# LRFDRFE register map
Vendor: Texas Instruments
Registers are 32-bit, access per field, reset 0x0 unless marked. A register's access mark holds for its fields unless they carry their own. Offsets are as the file gives them; [hi:lo] are bit positions; {n}, {i} and the like mark numbered series; 'fields as' and 'values as' point back to an identical list.

## LRFDRFE (part 2 of 2)
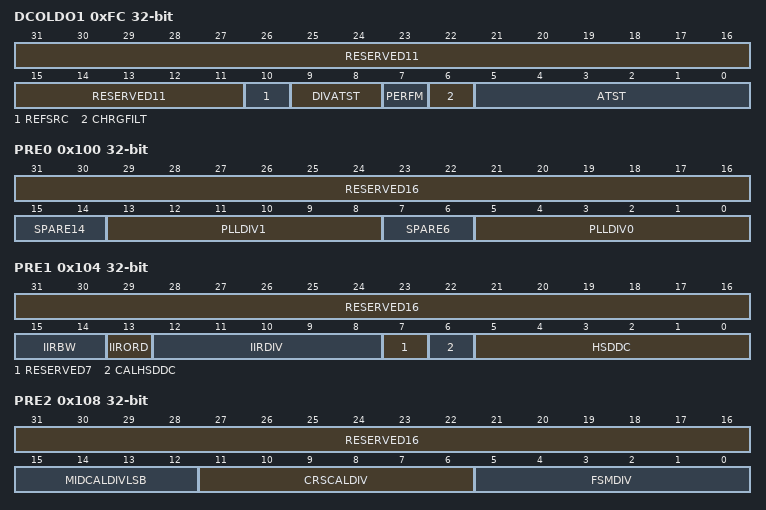
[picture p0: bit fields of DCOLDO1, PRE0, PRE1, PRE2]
0xFC DCOLDO1 — Internal. Only to be used through TI provided API.
  [31:11] RESERVED11 ro — Internal. Only to be used through TI provided API.
  [10] REFSRC rw — Internal. Only to be used through TI provided API.
    1=BAW (Internal. Only to be used through TI provided API.); 0=XTAL (Internal. Only to be used through TI provided API.)
  [9:8] DIVATST rw — Internal. Only to be used through TI provided API.
    3=ONES (Internal. Only to be used through TI provided API.); 0=ZEROS (Internal. Only to be used through TI provided API.)
  [7] PERFM rw — Internal. Only to be used through TI provided API.
    1=EN (Internal. Only to be used through TI provided API.); 0=DIS (Internal. Only to be used through TI provided API.)
  [6] CHRGFILT rw — Internal. Only to be used through TI provided API.
    values as PERFM
  [5:0] ATST rw — Internal. Only to be used through TI provided API.
    32=VSSANA (Internal. Only to be used through TI provided API.); 1=FIRST_OUT (Internal. Only to be used through TI provided API.); 0=LDO_OUT (Internal. Only to be used through TI provided API.)
0x100 PRE0 — Internal. Only to be used through TI provided API.
  [31:16] RESERVED16 ro — Internal. Only to be used through TI provided API.
  [15:14] SPARE14 rw — Internal. Only to be used through TI provided API.
    3=ALLONES (Internal. Only to be used through TI provided API.); 0=ALLZEROS (Internal. Only to be used through TI provided API.)
  [13:8] PLLDIV1 rw — Internal. Only to be used through TI provided API.
    63=ALLONES (Internal. Only to be used through TI provided API.); 0=ALLZEROS (Internal. Only to be used through TI provided API.)
  [7:6] SPARE6 rw — Internal. Only to be used through TI provided API.
    values as SPARE14
  [5:0] PLLDIV0 rw — Internal. Only to be used through TI provided API.
    values as PLLDIV1
0x104 PRE1 — Internal. Only to be used through TI provided API.
  [31:16] RESERVED16 ro — Internal. Only to be used through TI provided API.
  [15:14] IIRBW rw — Internal. Only to be used through TI provided API.
    3=K16 (Internal. Only to be used through TI provided API.); 2=K8 (Internal. Only to be used through TI provided API.); 1=K4 (Internal. Only to be used through TI provided API.); 0=K2 (Internal. Only to be used through TI provided API.)
  [13] IIRORD rw — Internal. Only to be used through TI provided API.
    1=SECOND (Internal. Only to be used through TI provided API.); 0=FIRST (Internal. Only to be used through TI provided API.)
  [12:8] IIRDIV rw — Internal. Only to be used through TI provided API.
    31=ALLONES (Internal. Only to be used through TI provided API.); 0=ALLZEROS (Internal. Only to be used through TI provided API.)
  [7] RESERVED7 ro — Internal. Only to be used through TI provided API.
  [6] CALHSDDC rw — Internal. Only to be used through TI provided API.
    1=GATE (Internal. Only to be used through TI provided API.); 0=NOGATE (Internal. Only to be used through TI provided API.)
  [5:0] HSDDC rw — Internal. Only to be used through TI provided API.
    values as PRE0.PLLDIV1
0x108 PRE2 — Internal. Only to be used through TI provided API.
  [31:16] RESERVED16 ro — Internal. Only to be used through TI provided API.
  [15:12] MIDCALDIVLSB rw — Internal. Only to be used through TI provided API.
    15=ALLONES (Internal. Only to be used through TI provided API.); 0=ALLZEROS (Internal. Only to be used through TI provided API.)
  [11:6] CRSCALDIV rw — Internal. Only to be used through TI provided API.
    values as PRE0.PLLDIV1
  [5:0] FSMDIV rw — Internal. Only to be used through TI provided API.
    values as PRE0.PLLDIV1
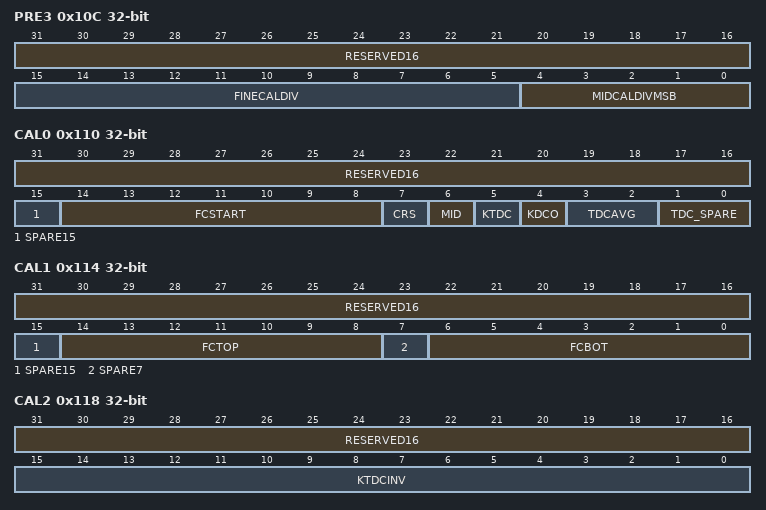
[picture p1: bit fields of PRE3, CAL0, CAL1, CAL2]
0x10C PRE3 — Internal. Only to be used through TI provided API.
  [31:16] RESERVED16 ro — Internal. Only to be used through TI provided API.
  [15:5] FINECALDIV rw — Internal. Only to be used through TI provided API.
    0x7FF=ALLONES (Internal. Only to be used through TI provided API.); 0=ALLZEROS (Internal. Only to be used through TI provided API.)
  [4:0] MIDCALDIVMSB rw — Internal. Only to be used through TI provided API.
    values as PRE1.IIRDIV
0x110 CAL0 — Internal. Only to be used through TI provided API.
  [31:16] RESERVED16 ro — Internal. Only to be used through TI provided API.
  [15] SPARE15 rw — Internal. Only to be used through TI provided API.
    1=ONE (Internal. Only to be used through TI provided API.); 0=ZERO (Internal. Only to be used through TI provided API.)
  [14:8] FCSTART rw — Internal. Only to be used through TI provided API.
    127=ALLONES (Internal. Only to be used through TI provided API.); 0=ALLZEROS (Internal. Only to be used through TI provided API.)
  [7] CRS rw — Internal. Only to be used through TI provided API.
    values as DCOLDO1.PERFM
  [6] MID rw — Internal. Only to be used through TI provided API.
    values as DCOLDO1.PERFM
  [5] KTDC rw — Internal. Only to be used through TI provided API.
    values as DCOLDO1.PERFM
  [4] KDCO rw — Internal. Only to be used through TI provided API.
    values as DCOLDO1.PERFM
  [3:2] TDCAVG rw — Internal. Only to be used through TI provided API.
    3=REPEAT_8_TIMES (Internal. Only to be used through TI provided API.); 2=REPEAT_4_TIMES (Internal. Only to be used through TI provided API.); 1=REPEAT_2_TIMES (Internal. Only to be used through TI provided API.); 0=REPEAT_1_TIME (Internal. Only to be used through TI provided API.)
  [1:0] TDC_SPARE rw — Internal. Only to be used through TI provided API.
    values as PRE0.SPARE14
0x114 CAL1 — Internal. Only to be used through TI provided API.
  [31:16] RESERVED16 ro — Internal. Only to be used through TI provided API.
  [15] SPARE15 rw — Internal. Only to be used through TI provided API.
    values as CAL0.SPARE15
  [14:8] FCTOP rw — Internal. Only to be used through TI provided API.
    values as CAL0.FCSTART
  [7] SPARE7 rw — Internal. Only to be used through TI provided API.
    values as CAL0.SPARE15
  [6:0] FCBOT rw — Internal. Only to be used through TI provided API.
    values as CAL0.FCSTART
0x118 CAL2 — Internal. Only to be used through TI provided API.
  [31:16] RESERVED16 ro — Internal. Only to be used through TI provided API.
  [15:0] KTDCINV rw — Internal. Only to be used through TI provided API.
    0xFFFF=ALLONES (Internal. Only to be used through TI provided API.); 0=ALLZEROS (Internal. Only to be used through TI provided API.)
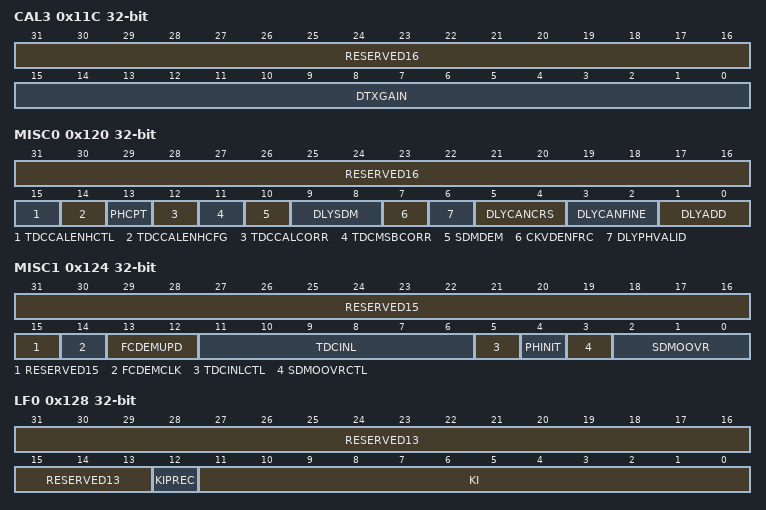
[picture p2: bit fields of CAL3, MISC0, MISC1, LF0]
0x11C CAL3 — Internal. Only to be used through TI provided API.
  [31:16] RESERVED16 ro — Internal. Only to be used through TI provided API.
  [15:0] DTXGAIN rw — Internal. Only to be used through TI provided API.
    values as CAL2.KTDCINV
0x120 MISC0 — Internal. Only to be used through TI provided API.
  [31:16] RESERVED16 ro — Internal. Only to be used through TI provided API.
  [15] TDCCALENHCTL rw — Internal. Only to be used through TI provided API.
    values as DCOLDO1.PERFM
  [14] TDCCALENHCFG rw — Internal. Only to be used through TI provided API.
    1=MAXOFFSET (Internal. Only to be used through TI provided API.); 0=MINOFFSET (Internal. Only to be used through TI provided API.)
  [13] PHCPT rw — Internal. Only to be used through TI provided API.
    1=ASYNC (Internal. Only to be used through TI provided API.); 0=SYNC (Internal. Only to be used through TI provided API.)
  [12] TDCCALCORR rw — Internal. Only to be used through TI provided API.
    values as DCOLDO1.PERFM
  [11] TDCMSBCORR rw — Internal. Only to be used through TI provided API.
    values as DCOLDO1.PERFM
  [10] SDMDEM rw — Internal. Only to be used through TI provided API.
    values as DCOLDO1.PERFM
  [9:8] DLYSDM rw — Internal. Only to be used through TI provided API.
    {v}=CKVD16_{v}_PER (Internal. Only to be used through TI provided API.) (v=0..3)
  [7] CKVDENFRC rw — Internal. Only to be used through TI provided API.
    values as DCOLDO1.PERFM
  [6] DLYPHVALID rw — Internal. Only to be used through TI provided API.
    1=NOQUAL (Internal. Only to be used through TI provided API.); 0=QUAL (Internal. Only to be used through TI provided API.)
  [5:4] DLYCANCRS rw — Internal. Only to be used through TI provided API.
    {v}=CKVD64_{v}_PER (Internal. Only to be used through TI provided API.) (v=0..3)
  [3:2] DLYCANFINE rw — Internal. Only to be used through TI provided API.
    {v}=CKVD16_{v+1}_PER (Internal. Only to be used through TI provided API.) (v=0..3)
  [1:0] DLYADD rw — Internal. Only to be used through TI provided API.
    values as DLYCANCRS
0x124 MISC1 — Internal. Only to be used through TI provided API.
  [31:15] RESERVED15 ro — Internal. Only to be used through TI provided API.
  [14] FCDEMCLK rw — Internal. Only to be used through TI provided API.
    1=CKVD64 (Internal. Only to be used through TI provided API.); 0=CKCD16 (Internal. Only to be used through TI provided API.)
  [13:12] FCDEMUPD rw — Internal. Only to be used through TI provided API.
    3=SDM_XOR_PH_ERR (Internal. Only to be used through TI provided API.); 2=SDM (Internal. Only to be used through TI provided API.); 1=PH_ERR (Internal. Only to be used through TI provided API.); 0=DEFAULT (Internal. Only to be used through TI provided API.)
  [11:6] TDCINL rw — Internal. Only to be used through TI provided API.
    63=ONES (Internal. Only to be used through TI provided API.); 0=ZEROS (Internal. Only to be used through TI provided API.)
  [5] TDCINLCTL rw — Internal. Only to be used through TI provided API.
    values as DCOLDO1.PERFM
  [4] PHINIT rw — Internal. Only to be used through TI provided API.
    1=UNKNOWN (Internal. Only to be used through TI provided API.); 0=KNOWN (Internal. Only to be used through TI provided API.)
  [3] SDMOOVRCTL rw — Internal. Only to be used through TI provided API.
    values as DCOLDO1.PERFM
  [2:0] SDMOOVR rw — Internal. Only to be used through TI provided API.
    7=ALLONES (Internal. Only to be used through TI provided API.); 0=ALLZEROS (Internal. Only to be used through TI provided API.)
0x128 LF0 — Internal. Only to be used through TI provided API.
  [31:13] RESERVED13 ro — Internal. Only to be used through TI provided API.
  [12] KIPREC rw — Internal. Only to be used through TI provided API.
    1=HIGH (Internal. Only to be used through TI provided API.); 0=LOW (Internal. Only to be used through TI provided API.)
  [11:0] KI rw — Internal. Only to be used through TI provided API.
    0xFFF=ALLONES (Internal. Only to be used through TI provided API.); 0=ALLZEROS (Internal. Only to be used through TI provided API.)
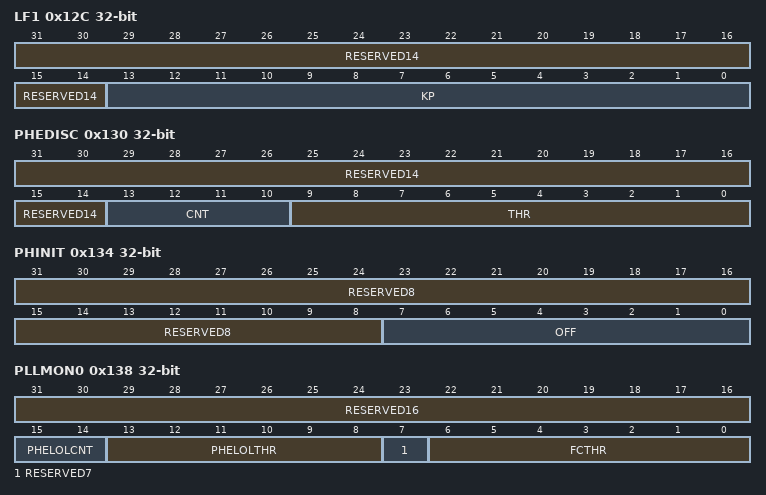
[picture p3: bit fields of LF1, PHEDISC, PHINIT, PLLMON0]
0x12C LF1 — Internal. Only to be used through TI provided API.
  [31:14] RESERVED14 ro — Internal. Only to be used through TI provided API.
  [13:0] KP rw — Internal. Only to be used through TI provided API.
    0x3FFF=ALLONES (Internal. Only to be used through TI provided API.); 0=ALLZEROS (Internal. Only to be used through TI provided API.)
0x130 PHEDISC — Internal. Only to be used through TI provided API.
  [31:14] RESERVED14 ro — Internal. Only to be used through TI provided API.
  [13:10] CNT rw — Internal. Only to be used through TI provided API.
    values as PRE2.MIDCALDIVLSB
  [9:0] THR rw — Internal. Only to be used through TI provided API.
    0x3FF=ALLONES (Internal. Only to be used through TI provided API.); 0=ALLZEROS (Internal. Only to be used through TI provided API.)
0x134 PHINIT — Internal. Only to be used through TI provided API.
  [31:8] RESERVED8 ro — Internal. Only to be used through TI provided API.
  [7:0] OFF rw — Internal. Only to be used through TI provided API.
    255=ALLONES (Internal. Only to be used through TI provided API.); 0=ALLZEROS (Internal. Only to be used through TI provided API.)
0x138 PLLMON0 — Internal. Only to be used through TI provided API.
  [31:16] RESERVED16 ro — Internal. Only to be used through TI provided API.
  [15:14] PHELOLCNT rw — Internal. Only to be used through TI provided API.
    3=REFCLK_128_PER (Internal. Only to be used through TI provided API.); 2=REFCLK_64_PER (Internal. Only to be used through TI provided API.); 1=REFCLK_32_PER (Internal. Only to be used through TI provided API.); 0=REFCLK_16_PER (Internal. Only to be used through TI provided API.)
  [13:8] PHELOLTHR rw — Internal. Only to be used through TI provided API.
    values as PRE0.PLLDIV1
  [7] RESERVED7 ro — Internal. Only to be used through TI provided API.
  [6:0] FCTHR rw — Internal. Only to be used through TI provided API.
    values as CAL0.FCSTART
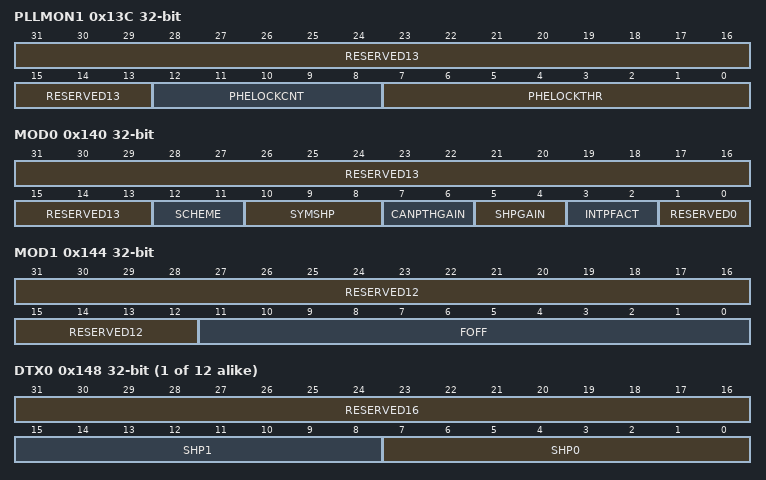
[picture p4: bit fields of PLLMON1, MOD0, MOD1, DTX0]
0x13C PLLMON1 — Internal. Only to be used through TI provided API.
  [31:13] RESERVED13 ro — Internal. Only to be used through TI provided API.
  [12:8] PHELOCKCNT rw — Internal. Only to be used through TI provided API.
    values as PRE1.IIRDIV
  [7:0] PHELOCKTHR rw — Internal. Only to be used through TI provided API.
    values as PHINIT.OFF
0x140 MOD0 — Internal. Only to be used through TI provided API.
  [31:13] RESERVED13 ro — Internal. Only to be used through TI provided API.
  [12:11] SCHEME rw — Internal. Only to be used through TI provided API.
    3=TWO_POINT_MOD_FRF (Internal. Only to be used through TI provided API.); 2=INLOOP_MOD_FRF (Internal. Only to be used through TI provided API.); 1=INLOOP_MOD_FREF (Internal. Only to be used through TI provided API.); 0=NC (Internal. Only to be used through TI provided API.)
  [10:8] SYMSHP rw — Internal. Only to be used through TI provided API.
    4=CHIRP (Internal. Only to be used through TI provided API.); 3=SHAPEDZIGBEE (Internal. Only to be used through TI provided API.); 2=PCWSPSK (Internal. Only to be used through TI provided API.); 1=ZIGBEE (Internal. Only to be used through TI provided API.); 0=SHAPEDFSK (Internal. Only to be used through TI provided API.)
  [7:6] CANPTHGAIN rw — Internal. Only to be used through TI provided API.
    {v}=TWO_POW_M_{v+15} (Internal. Only to be used through TI provided API.) (v=0..3)
  [5:4] SHPGAIN rw — Internal. Only to be used through TI provided API.
    3=X8 (Internal. Only to be used through TI provided API.); 2=X4 (Internal. Only to be used through TI provided API.); 1=X2 (Internal. Only to be used through TI provided API.); 0=Internal. Only to be used through TI provided API.
  [3:2] INTPFACT rw — Internal. Only to be used through TI provided API.
    3=ILLEGAL1 (Internal. Only to be used through TI provided API.); 2=INTP_BY_32 (Internal. Only to be used through TI provided API.); 1=INTP_BY_16 (Internal. Only to be used through TI provided API.); 0=ILLEGAL0 (Internal. Only to be used through TI provided API.)
  [1:0] RESERVED0 ro — Internal. Only to be used through TI provided API.
0x144 MOD1 — Internal. Only to be used through TI provided API.
  [31:12] RESERVED12 ro — Internal. Only to be used through TI provided API.
  [11:0] FOFF rw — Internal. Only to be used through TI provided API.
    values as LF0.KI
{0x148+4i} DTX{i} (i=0..11) — Internal. Only to be used through TI provided API.
  [31:16] RESERVED16 ro — Internal. Only to be used through TI provided API.
  [15:8] SHP{2i+1} rw — Internal. Only to be used through TI provided API.
    values as PHINIT.OFF
  [7:0] SHP{2i} rw — Internal. Only to be used through TI provided API.
    values as PHINIT.OFF
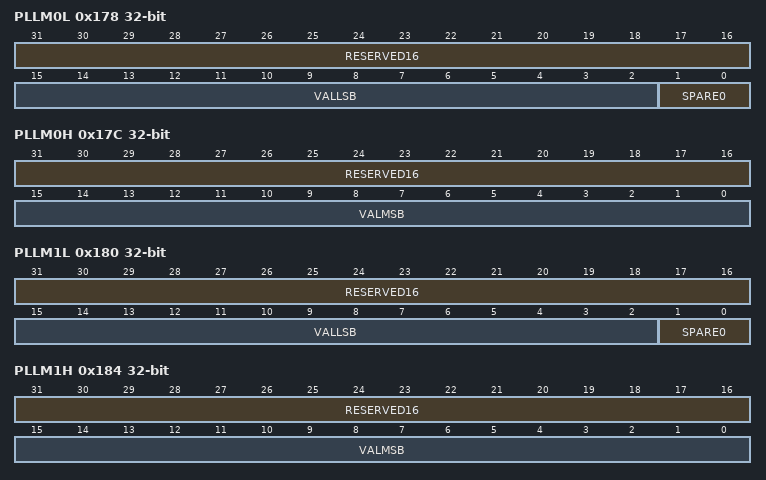
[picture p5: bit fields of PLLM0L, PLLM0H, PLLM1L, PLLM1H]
0x178 PLLM0L — Internal. Only to be used through TI provided API.
  [31:16] RESERVED16 ro — Internal. Only to be used through TI provided API.
  [15:2] VALLSB rw — Internal. Only to be used through TI provided API.
    values as LF1.KP
  [1:0] SPARE0 rw — Internal. Only to be used through TI provided API.
    values as PRE0.SPARE14
0x17C PLLM0H — Internal. Only to be used through TI provided API.
  [31:16] RESERVED16 ro — Internal. Only to be used through TI provided API.
  [15:0] VALMSB rw — Internal. Only to be used through TI provided API.
    values as CAL2.KTDCINV
0x180 PLLM1L — Internal. Only to be used through TI provided API.
  fields as PLLM0L
0x184 PLLM1H — Internal. Only to be used through TI provided API.
  fields as PLLM0H
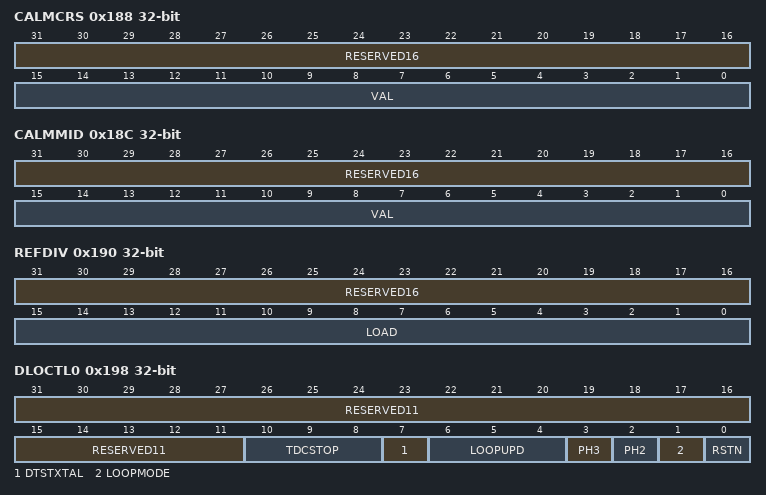
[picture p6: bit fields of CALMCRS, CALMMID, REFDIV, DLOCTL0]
0x188 CALMCRS — Internal. Only to be used through TI provided API.
  [31:16] RESERVED16 ro — Internal. Only to be used through TI provided API.
  [15:0] VAL rw — Internal. Only to be used through TI provided API.
    values as CAL2.KTDCINV
0x18C CALMMID — Internal. Only to be used through TI provided API.
  fields as CALMCRS
0x190 REFDIV — Internal. Only to be used through TI provided API.
  [31:16] RESERVED16 ro — Internal. Only to be used through TI provided API.
  [15:0] LOAD rw — Internal. Only to be used through TI provided API.
    values as CAL2.KTDCINV
0x198 DLOCTL0 — Internal. Only to be used through TI provided API.
  [31:11] RESERVED11 ro — Internal. Only to be used through TI provided API.
  [10:8] TDCSTOP rw — Internal. Only to be used through TI provided API.
    1=OPEN (Internal. Only to be used through TI provided API.); 0=CLOSED (Internal. Only to be used through TI provided API.)
  [7] DTSTXTAL rw — Internal. Only to be used through TI provided API.
    values as CAL0.SPARE15
  [6:4] LOOPUPD rw — Internal. Only to be used through TI provided API.
    1=ALT (Internal. Only to be used through TI provided API.); 0=DEF (Internal. Only to be used through TI provided API.)
  [3] PH3 rw — Internal. Only to be used through TI provided API.
    1=START (Internal. Only to be used through TI provided API.); 0=HALT (Internal. Only to be used through TI provided API.)
  [2] PH2 rw — Internal. Only to be used through TI provided API.
    values as PH3
  [1] LOOPMODE rw — Internal. Only to be used through TI provided API.
    values as TDCSTOP
  [0] RSTN rw — Internal. Only to be used through TI provided API.
    1=ACTIVE (Internal. Only to be used through TI provided API.); 0=RESET (Internal. Only to be used through TI provided API.)
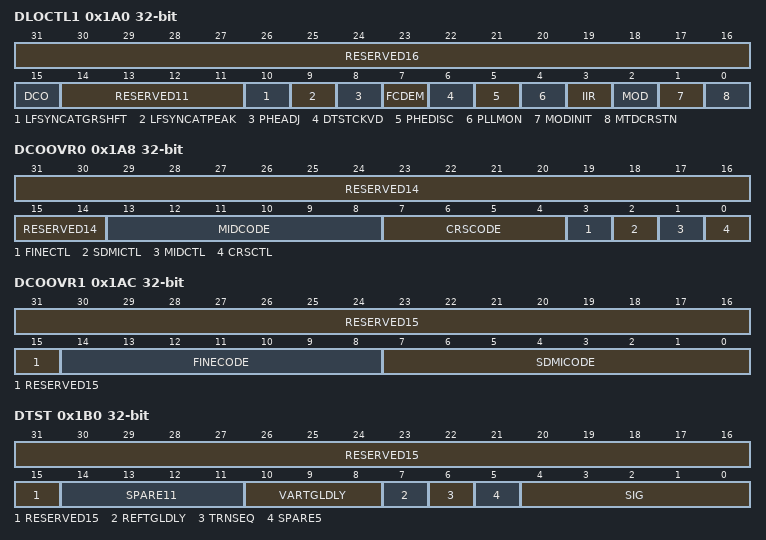
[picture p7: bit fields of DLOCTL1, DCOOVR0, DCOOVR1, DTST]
0x1A0 DLOCTL1 — Internal. Only to be used through TI provided API.
  [31:16] RESERVED16 ro — Internal. Only to be used through TI provided API.
  [15] DCO rw — Internal. Only to be used through TI provided API.
    values as DCOLDO1.PERFM
  [14:11] RESERVED11 ro — Internal. Only to be used through TI provided API.
  [10] LFSYNCATGRSHFT rw — Internal. Only to be used through TI provided API.
    values as DCOLDO1.PERFM
  [9] LFSYNCATPEAK rw — Internal. Only to be used through TI provided API.
    values as DCOLDO1.PERFM
  [8] PHEADJ rw — Internal. Only to be used through TI provided API.
    values as DCOLDO1.PERFM
  [7] FCDEM rw — Internal. Only to be used through TI provided API.
    values as DCOLDO1.PERFM
  [6] DTSTCKVD rw — Internal. Only to be used through TI provided API.
    values as CAL0.SPARE15
  [5] PHEDISC rw — Internal. Only to be used through TI provided API.
    values as DCOLDO1.PERFM
  [4] PLLMON rw — Internal. Only to be used through TI provided API.
    values as DCOLDO1.PERFM
  [3] IIR rw — Internal. Only to be used through TI provided API.
    values as DCOLDO1.PERFM
  [2] MOD rw — Internal. Only to be used through TI provided API.
    values as DCOLDO1.PERFM
  [1] MODINIT rw — Internal. Only to be used through TI provided API.
    1=ACTIVATE (Internal. Only to be used through TI provided API.); 0=DEACTIVATE (Internal. Only to be used through TI provided API.)
  [0] MTDCRSTN rw — Internal. Only to be used through TI provided API.
    values as DLOCTL0.RSTN
0x1A8 DCOOVR0 — Internal. Only to be used through TI provided API.
  [31:14] RESERVED14 ro — Internal. Only to be used through TI provided API.
  [13:8] MIDCODE rw — Internal. Only to be used through TI provided API.
    values as PRE0.PLLDIV1
  [7:4] CRSCODE rw — Internal. Only to be used through TI provided API.
    values as PRE2.MIDCALDIVLSB
  [3] FINECTL rw — Internal. Only to be used through TI provided API.
    values as DCOLDO1.PERFM
  [2] SDMICTL rw — Internal. Only to be used through TI provided API.
    values as DCOLDO1.PERFM
  [1] MIDCTL rw — Internal. Only to be used through TI provided API.
    values as DCOLDO1.PERFM
  [0] CRSCTL rw — Internal. Only to be used through TI provided API.
    values as DCOLDO1.PERFM
0x1AC DCOOVR1 — Internal. Only to be used through TI provided API.
  [31:15] RESERVED15 ro — Internal. Only to be used through TI provided API.
  [14:8] FINECODE rw — Internal. Only to be used through TI provided API.
    values as CAL0.FCSTART
  [7:0] SDMICODE rw — Internal. Only to be used through TI provided API.
    values as PHINIT.OFF
0x1B0 DTST — Internal. Only to be used through TI provided API.
  [31:15] RESERVED15 ro — Internal. Only to be used through TI provided API.
  [14:11] SPARE11 rw — Internal. Only to be used through TI provided API.
    values as PRE2.MIDCALDIVLSB
  [10:8] VARTGLDLY rw — Internal. Only to be used through TI provided API.
    {v}=CLK_{v}_PER (Internal. Only to be used through TI provided API.) (v=0..7)
  [7] REFTGLDLY rw — Internal. Only to be used through TI provided API.
    1=CLK_1_PER (Internal. Only to be used through TI provided API.); 0=CLK_0_PER (Internal. Only to be used through TI provided API.)
  [6] TRNSEQ rw — Internal. Only to be used through TI provided API.
    values as DCOLDO1.PERFM
  [5] SPARE5 rw — Internal. Only to be used through TI provided API.
    values as CAL0.SPARE15
  [4:0] SIG rw — Internal. Only to be used through TI provided API.
    31=VAR_NC_15 (Internal. Only to be used through TI provided API.); 30=VAR_NC_14 (Internal. Only to be used through TI provided API.); 29=VAR_NC_13 (Internal. Only to be used through TI provided API.); 28=VAR_FCPHELFSYNC (Internal. Only to be used through TI provided API.); 27=VAR_FCPHE (Internal. Only to be used through TI provided API.); 26=VAR_LOOP_UPD_FINECODE (Internal. Only to be used through TI provided API.); 25=VAR_LOCK_FINECODE (Internal. Only to be used through TI provided API.); 24=VAR_MPX_CAN (Internal. Only to be used through TI provided API.); 23=VAR_TDCSTOP_STATUS_TDC (Internal. Only to be used through TI provided API.); 22=VAR_TDCSTOP_PHERR (Internal. Only to be used through TI provided API.); 21=VAR_PH_COMP_PHERR_TDCSTOP (Internal. Only to be used through TI provided API.); 20=VAR_PH_TDCCORR (Internal. Only to be used through TI provided API.); 19=VAR_PH_RAW (Internal. Only to be used through TI provided API.); 18=VAR_PHERR_LOWER (Internal. Only to be used through TI provided API.); 17=VAR_PHERR_UPPER (Internal. Only to be used through TI provided API.); 16=VAR_NC_0 (Internal. Only to be used through TI provided API.); {v}=REF_NC_{v} (Internal. Only to be used through TI provided API.) (v=3..15); 2=REF_FERR_MAG (Internal. Only to be used through TI provided API.); 1=REF_FSMCAL (Internal. Only to be used through TI provided API.); 0=REF_NC_0 (Internal. Only to be used through TI provided API.)
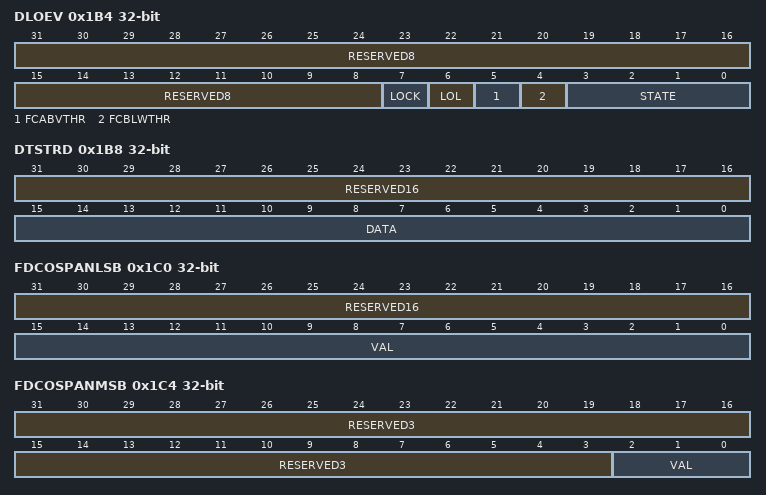
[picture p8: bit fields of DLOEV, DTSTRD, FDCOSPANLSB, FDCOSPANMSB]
0x1B4 DLOEV ro — Internal. Only to be used through TI provided API.
  [31:8] RESERVED8 — Internal. Only to be used through TI provided API.
  [7] LOCK — Internal. Only to be used through TI provided API.
    values as CAL0.SPARE15
  [6] LOL — Internal. Only to be used through TI provided API.
    values as CAL0.SPARE15
  [5] FCABVTHR — Internal. Only to be used through TI provided API.
    values as CAL0.SPARE15
  [4] FCBLWTHR — Internal. Only to be used through TI provided API.
    values as CAL0.SPARE15
  [3:0] STATE — Internal. Only to be used through TI provided API.
    values as PRE2.MIDCALDIVLSB
0x1B8 DTSTRD ro — Internal. Only to be used through TI provided API.
  [31:16] RESERVED16 — Internal. Only to be used through TI provided API.
  [15:0] DATA — Internal. Only to be used through TI provided API.
    values as CAL2.KTDCINV
0x1C0 FDCOSPANLSB ro — Internal. Only to be used through TI provided API.
  [31:16] RESERVED16 — Internal. Only to be used through TI provided API.
  [15:0] VAL — Internal. Only to be used through TI provided API.
    values as CAL2.KTDCINV
0x1C4 FDCOSPANMSB ro — Internal. Only to be used through TI provided API.
  [31:3] RESERVED3 — Internal. Only to be used through TI provided API.
  [2:0] VAL — Internal. Only to be used through TI provided API.
    values as MISC1.SDMOOVR
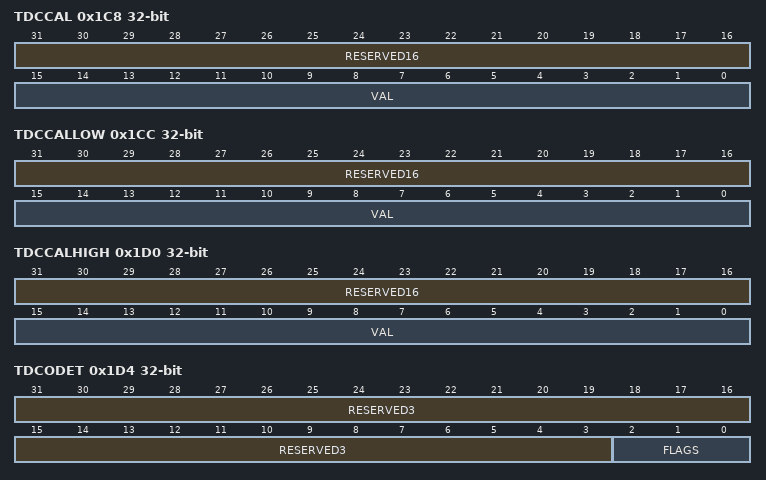
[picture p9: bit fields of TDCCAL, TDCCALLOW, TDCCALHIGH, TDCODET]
0x1C8 TDCCAL ro — Internal. Only to be used through TI provided API.
  fields as FDCOSPANLSB
0x1CC TDCCALLOW ro — Internal. Only to be used through TI provided API.
  fields as FDCOSPANLSB
0x1D0 TDCCALHIGH ro — Internal. Only to be used through TI provided API.
  fields as FDCOSPANLSB
0x1D4 TDCODET ro — Internal. Only to be used through TI provided API.
  [31:3] RESERVED3 — Internal. Only to be used through TI provided API.
  [2:0] FLAGS — Internal. Only to be used through TI provided API.
    values as MISC1.SDMOOVR
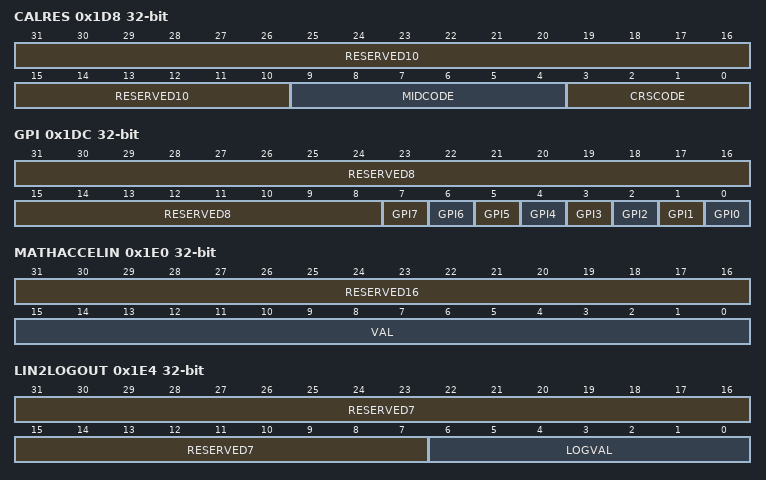
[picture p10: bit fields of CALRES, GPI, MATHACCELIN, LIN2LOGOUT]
0x1D8 CALRES ro — Internal. Only to be used through TI provided API.
  [31:10] RESERVED10 — Internal. Only to be used through TI provided API.
  [9:4] MIDCODE — Internal. Only to be used through TI provided API.
    values as PRE0.PLLDIV1
  [3:0] CRSCODE — Internal. Only to be used through TI provided API.
    values as PRE2.MIDCALDIVLSB
0x1DC GPI ro — Internal. Only to be used through TI provided API.
  [31:8] RESERVED8 — Internal. Only to be used through TI provided API.
  [n] GPI{n} (n=0..7) — Internal. Only to be used through TI provided API.
    values as CAL0.SPARE15
0x1E0 MATHACCELIN — Internal. Only to be used through TI provided API.
  fields as CALMCRS
0x1E4 LIN2LOGOUT ro — Internal. Only to be used through TI provided API.
  [31:7] RESERVED7 — Internal. Only to be used through TI provided API.
  [6:0] LOGVAL — Internal. Only to be used through TI provided API.
    values as CAL0.FCSTART
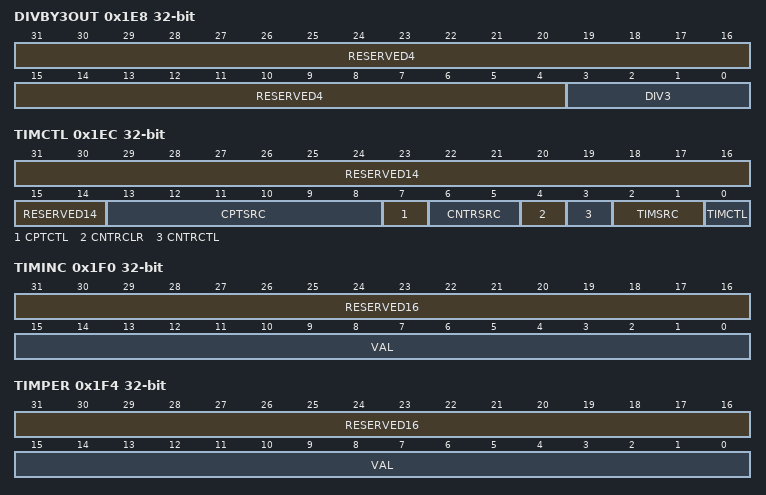
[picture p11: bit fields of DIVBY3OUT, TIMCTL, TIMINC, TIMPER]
0x1E8 DIVBY3OUT ro — Internal. Only to be used through TI provided API.
  [31:4] RESERVED4 — Internal. Only to be used through TI provided API.
  [3:0] DIV3 — Internal. Only to be used through TI provided API.
    values as PRE2.MIDCALDIVLSB
0x1EC TIMCTL — Internal. Only to be used through TI provided API.
  [31:14] RESERVED14 ro — Internal. Only to be used through TI provided API.
  [13:8] CPTSRC rw — Internal. Only to be used through TI provided API.
    values as PRE0.PLLDIV1
  [7] CPTCTL rw — Internal. Only to be used through TI provided API.
    values as DCOLDO1.PERFM
  [6:5] CNTRSRC rw — Internal. Only to be used through TI provided API.
    3=FREF (Internal. Only to be used through TI provided API.); 2=MAGN1 (Internal. Only to be used through TI provided API.); 1=MAGN0 (Internal. Only to be used through TI provided API.); 0=CLK (Internal. Only to be used through TI provided API.)
  [4] CNTRCLR rw — Internal. Only to be used through TI provided API.
    values as CAL0.SPARE15
  [3] CNTRCTL rw — Internal. Only to be used through TI provided API.
    values as DCOLDO1.PERFM
  [2:1] TIMSRC rw — Internal. Only to be used through TI provided API.
    values as CNTRSRC
  [0] TIMCTL rw — Internal. Only to be used through TI provided API.
    values as DCOLDO1.PERFM
0x1F0 TIMINC — Internal. Only to be used through TI provided API.
  fields as CALMCRS
0x1F4 TIMPER — Internal. Only to be used through TI provided API.
  fields as CALMCRS
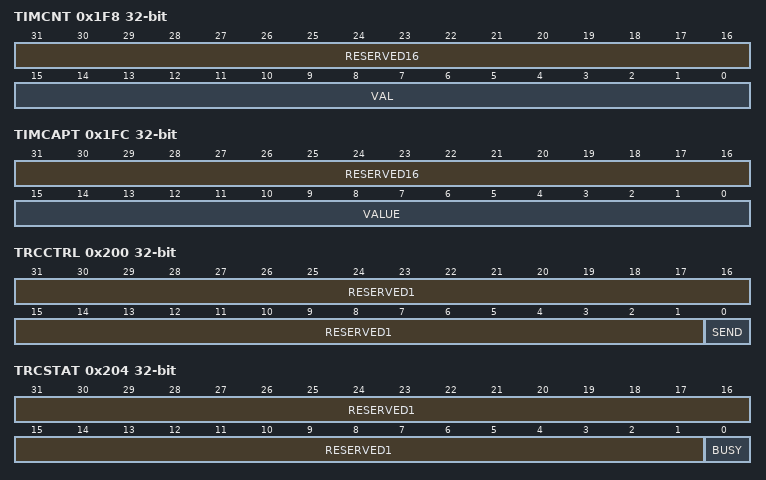
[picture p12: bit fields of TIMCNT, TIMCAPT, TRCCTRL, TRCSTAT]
0x1F8 TIMCNT ro — Internal. Only to be used through TI provided API.
  fields as FDCOSPANLSB
0x1FC TIMCAPT ro — Internal. Only to be used through TI provided API.
  [31:16] RESERVED16 — Internal. Only to be used through TI provided API.
  [15:0] VALUE — Internal. Only to be used through TI provided API.
    values as CAL2.KTDCINV
0x200 TRCCTRL — Internal. Only to be used through TI provided API.
  [31:1] RESERVED1 ro — Internal. Only to be used through TI provided API.
  [0] SEND wo — Internal. Only to be used through TI provided API.
    values as CAL0.SPARE15
0x204 TRCSTAT ro — Internal. Only to be used through TI provided API.
  [31:1] RESERVED1 — Internal. Only to be used through TI provided API.
  [0] BUSY — Internal. Only to be used through TI provided API.
    values as CAL0.SPARE15
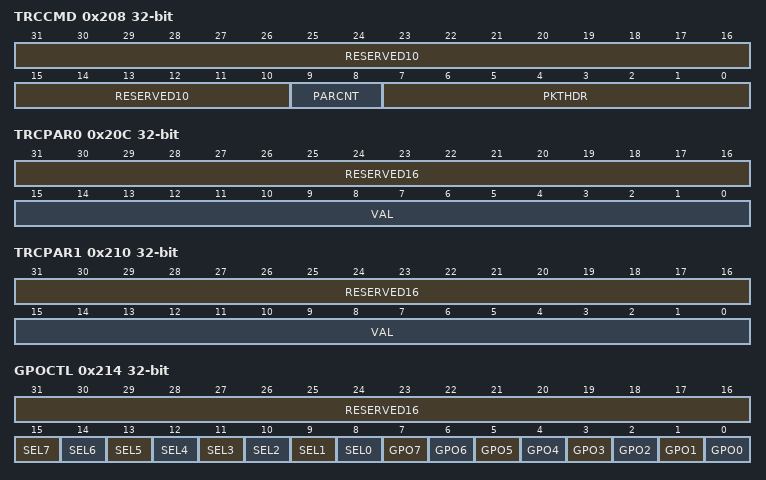
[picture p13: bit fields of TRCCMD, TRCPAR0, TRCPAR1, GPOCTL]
0x208 TRCCMD — Internal. Only to be used through TI provided API.
  [31:10] RESERVED10 ro — Internal. Only to be used through TI provided API.
  [9:8] PARCNT rw — Internal. Only to be used through TI provided API.
    values as PRE0.SPARE14
  [7:0] PKTHDR rw — Internal. Only to be used through TI provided API.
    values as PHINIT.OFF
0x20C TRCPAR0 — Internal. Only to be used through TI provided API.
  fields as CALMCRS
0x210 TRCPAR1 — Internal. Only to be used through TI provided API.
  fields as CALMCRS
0x214 GPOCTL — Internal. Only to be used through TI provided API.
  [31:16] RESERVED16 ro — Internal. Only to be used through TI provided API.
  [n+8] SEL{n} rw (n=0..7) — Internal. Only to be used through TI provided API.
    1=HW (Internal. Only to be used through TI provided API.); 0=SW (Internal. Only to be used through TI provided API.)
  [n] GPO{n} rw (n=0..7) — Internal. Only to be used through TI provided API.
    values as CAL0.SPARE15
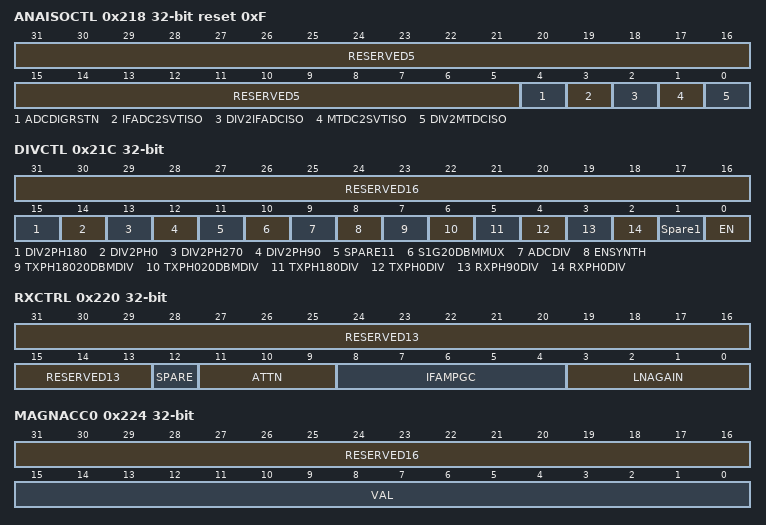
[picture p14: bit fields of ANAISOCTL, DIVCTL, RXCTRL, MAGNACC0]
0x218 ANAISOCTL reset 0xF — Internal. Only to be used through TI provided API.
  [31:5] RESERVED5 ro — Internal. Only to be used through TI provided API.
  [4] ADCDIGRSTN rw — Internal. Only to be used through TI provided API.
    values as DLOCTL0.RSTN
  [3] IFADC2SVTISO rw — Internal. Only to be used through TI provided API.
    1=ISOLATE (Internal. Only to be used through TI provided API.); 0=CONNECT (Internal. Only to be used through TI provided API.)
  [2] DIV2IFADCISO rw — Internal. Only to be used through TI provided API.
    values as IFADC2SVTISO
  [1] MTDC2SVTISO rw — Internal. Only to be used through TI provided API.
    values as IFADC2SVTISO
  [0] DIV2MTDCISO rw — Internal. Only to be used through TI provided API.
    values as IFADC2SVTISO
0x21C DIVCTL — Internal. Only to be used through TI provided API.
  [31:16] RESERVED16 ro — Internal. Only to be used through TI provided API.
  [15] DIV2PH180 rw — Internal. Only to be used through TI provided API.
    values as DCOLDO1.PERFM
  [14] DIV2PH0 rw — Internal. Only to be used through TI provided API.
    values as DCOLDO1.PERFM
  [13] DIV2PH270 rw — Internal. Only to be used through TI provided API.
    values as DCOLDO1.PERFM
  [12] DIV2PH90 rw — Internal. Only to be used through TI provided API.
    values as DCOLDO1.PERFM
  [11] SPARE11 rw — Internal. Only to be used through TI provided API.
    values as CAL0.SPARE15
  [10] S1G20DBMMUX rw — Internal. Only to be used through TI provided API.
    1=DISABLE (Internal. Only to be used through TI provided API.); 0=ENABLEN (Internal. Only to be used through TI provided API.)
  [9] ADCDIV rw — Internal. Only to be used through TI provided API.
    values as DCOLDO1.PERFM
  [8] ENSYNTH rw — Internal. Only to be used through TI provided API.
    values as DCOLDO1.PERFM
  [7] TXPH18020DBMDIV rw — Internal. Only to be used through TI provided API.
    values as DCOLDO1.PERFM
  [6] TXPH020DBMDIV rw — Internal. Only to be used through TI provided API.
    values as DCOLDO1.PERFM
  [5] TXPH180DIV rw — Internal. Only to be used through TI provided API.
    values as DCOLDO1.PERFM
  [4] TXPH0DIV rw — Internal. Only to be used through TI provided API.
    values as DCOLDO1.PERFM
  [3] RXPH90DIV rw — Internal. Only to be used through TI provided API.
    values as DCOLDO1.PERFM
  [2] RXPH0DIV rw — Internal. Only to be used through TI provided API.
    values as DCOLDO1.PERFM
  [1] Spare1 rw — Internal. Only to be used through TI provided API.
    values as CAL0.SPARE15
  [0] EN rw — Internal. Only to be used through TI provided API.
    1=ON (Internal. Only to be used through TI provided API.); 0=OFF (Internal. Only to be used through TI provided API.)
0x220 RXCTRL — Internal. Only to be used through TI provided API.
  [31:13] RESERVED13 ro — Internal. Only to be used through TI provided API.
  [12] SPARE rw — Internal. Only to be used through TI provided API.
    values as CAL0.SPARE15
  [11:9] ATTN rw — Internal. Only to be used through TI provided API.
    7=_21DB (Internal. Only to be used through TI provided API.); 6=_18DB (Internal. Only to be used through TI provided API.); 5=_15DB (Internal. Only to be used through TI provided API.); 4=_12DB (Internal. Only to be used through TI provided API.); 3=_9DB (Internal. Only to be used through TI provided API.); 2=_6DB (Internal. Only to be used through TI provided API.); 1=_3DB (Internal. Only to be used through TI provided API.); 0=NOATT (Internal. Only to be used through TI provided API.)
  [8:4] IFAMPGC rw — Internal. Only to be used through TI provided API.
    31=MAX (Internal. Only to be used through TI provided API.); 15=MIN3DB (Internal. Only to be used through TI provided API.); 7=MIN6DB (Internal. Only to be used through TI provided API.); 3=MIN9DB (Internal. Only to be used through TI provided API.); 1=MIN12DB (Internal. Only to be used through TI provided API.); 0=MIN15DB (Internal. Only to be used through TI provided API.)
  [3:0] LNAGAIN rw — Internal. Only to be used through TI provided API.
    15=MAX (Internal. Only to be used through TI provided API.); 7=MIN3DB (Internal. Only to be used through TI provided API.); 3=MIN6DB (Internal. Only to be used through TI provided API.); 1=MIN9DB (Internal. Only to be used through TI provided API.); 0=MIN12DB (Internal. Only to be used through TI provided API.)
0x224 MAGNACC0 ro — Internal. Only to be used through TI provided API.
  fields as FDCOSPANLSB
0x228 MAGNACC1 ro — Internal. Only to be used through TI provided API.
  fields as FDCOSPANLSB
0x22C RSSI — Internal. Only to be used through TI provided API.
  [31:8] RESERVED8 ro — Internal. Only to be used through TI provided API.
  [7:0] VAL rw — Internal. Only to be used through TI provided API.
    values as PHINIT.OFF
0x230 RSSIMAX — Internal. Only to be used through TI provided API.
  fields as RSSI
0x234 RFGAIN — Internal. Only to be used through TI provided API.
  [31:8] RESERVED8 ro — Internal. Only to be used through TI provided API.
  [7:0] DBGAIN rw — Internal. Only to be used through TI provided API.
    values as PHINIT.OFF
0x238 IFADCSTAT ro — Internal. Only to be used through TI provided API.
  [31:8] RESERVED8 — Internal. Only to be used through TI provided API.
  [7] RESERVED7 — Internal. Only to be used through TI provided API.
    values as CAL0.SPARE15
  [6:2] QUANTCALVAL — Internal. Only to be used through TI provided API.
    1=COMP1 (Internal. Only to be used through TI provided API.); 0=COMP0 (Internal. Only to be used through TI provided API.)
  [1] QUANTCALDONE — Internal. Only to be used through TI provided API.
    1=READY (Internal. Only to be used through TI provided API.); 0=NOT_READY (Internal. Only to be used through TI provided API.)
  [0] RESERVED0 — Internal. Only to be used through TI provided API.
    values as CAL0.SPARE15
0x23C DIVSTA ro — Internal. Only to be used through TI provided API.
  [31:1] RESERVED1 — Internal. Only to be used through TI provided API.
  [0] STAT — Internal. Only to be used through TI provided API.
    1=BUSY (Internal. Only to be used through TI provided API.); 0=IDLE (Internal. Only to be used through TI provided API.)
0x240 DIVIDENDL — Internal. Only to be used through TI provided API.
  [31:16] RESERVED16 ro — Internal. Only to be used through TI provided API.
  [15:0] VALLSB wo — Internal. Only to be used through TI provided API.
    values as CAL2.KTDCINV
0x244 DIVIDENDH — Internal. Only to be used through TI provided API.
  [31:16] RESERVED16 ro — Internal. Only to be used through TI provided API.
  [15:0] VALMSB wo — Internal. Only to be used through TI provided API.
    values as CAL2.KTDCINV
0x248 DIVISORL — Internal. Only to be used through TI provided API.
  [31:16] RESERVED16 ro — Internal. Only to be used through TI provided API.
  [15:0] VALLSB rw — Internal. Only to be used through TI provided API.
    values as CAL2.KTDCINV
0x24C DIVISORH — Internal. Only to be used through TI provided API.
  fields as PLLM0H
0x250 QUOTIENTL ro — Internal. Only to be used through TI provided API.
  [31:16] RESERVED16 — Internal. Only to be used through TI provided API.
  [15:0] VALLSB — Internal. Only to be used through TI provided API.
    values as CAL2.KTDCINV
0x254 QUOTIENTH ro — Internal. Only to be used through TI provided API.
  [31:16] RESERVED16 — Internal. Only to be used through TI provided API.
  [15:0] VALMSB — Internal. Only to be used through TI provided API.
    values as CAL2.KTDCINV
0x258 PRODUCTL ro — Internal. Only to be used through TI provided API.
  fields as QUOTIENTL
0x25C PRODUCTH ro — Internal. Only to be used through TI provided API.
  fields as QUOTIENTH
0x260 MULTSTA ro — Internal. Only to be used through TI provided API.
  fields as DIVSTA
0x268 MULTCFG — Internal. Only to be used through TI provided API.
  [31:1] RESERVED1 ro — Internal. Only to be used through TI provided API.
  [0] MODE rw — Internal. Only to be used through TI provided API.
    1=SIGNED (Internal. Only to be used through TI provided API.); 0=UNSIGNED (Internal. Only to be used through TI provided API.)
0x26C PA1 — Internal. Only to be used through TI provided API.
  [31:16] RESERVED16 ro — Internal. Only to be used through TI provided API.
  [15:13] SPARE0 rw — Internal. Only to be used through TI provided API.
    7=MAX (Internal. Only to be used through TI provided API.); 0=MIN (Internal. Only to be used through TI provided API.)
  [12:11] MODE rw — Internal. Only to be used through TI provided API.
    3=DBM20 (Internal. Only to be used through TI provided API.); 2=DBM12 (Internal. Only to be used through TI provided API.); 1=DBM5 (Internal. Only to be used through TI provided API.); 0=DBM0 (Internal. Only to be used through TI provided API.)
  [10:8] GAIN rw — Internal. Only to be used through TI provided API.
    values as SPARE0
  [7:2] IB rw — Internal. Only to be used through TI provided API.
    63=MAX (Internal. Only to be used through TI provided API.); 0=MIN (Internal. Only to be used through TI provided API.)
  [1:0] IBBOOST rw — Internal. Only to be used through TI provided API.
    3=MAX (Internal. Only to be used through TI provided API.); 0=MIN (Internal. Only to be used through TI provided API.)
0x270 PA2 — Internal. Only to be used through TI provided API.
  [31:16] RESERVED16 ro — Internal. Only to be used through TI provided API.
  [15:5] SPARE5 rw — Internal. Only to be used through TI provided API.
    0x7FF=MAX (Internal. Only to be used through TI provided API.); 0=MIN (Internal. Only to be used through TI provided API.)
  [4:0] TRIM rw — Internal. Only to be used through TI provided API.
    31=MAX (Internal. Only to be used through TI provided API.); 0=MIN (Internal. Only to be used through TI provided API.)
